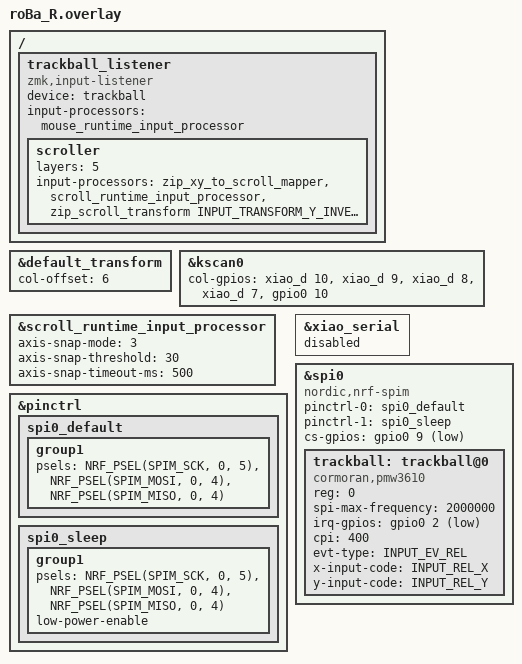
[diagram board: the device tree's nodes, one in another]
#include "roBa.dtsi"
#include <input/processors.dtsi>
#include <input/processors/runtime-input-processor.dtsi>
#include <behaviors/battery_history_request.dtsi>
#include <dt-bindings/zmk/input_transform.h>

&default_transform {
    col-offset = <6>;
};

&kscan0 {
        col-gpios
            = <&xiao_d 10 GPIO_ACTIVE_HIGH>
            , <&xiao_d 9 GPIO_ACTIVE_HIGH>
            , <&xiao_d 8 GPIO_ACTIVE_HIGH>
            , <&xiao_d 7 GPIO_ACTIVE_HIGH>
            , <&gpio0 10 GPIO_ACTIVE_HIGH>
            ;
};

/ {
    trackball_listener {
        status = "okay";
        compatible = "zmk,input-listener";
        device = <&trackball>;
        input-processors = <&mouse_runtime_input_processor>;

        scroller {
            layers = <5>;
            input-processors =
                <&zip_xy_to_scroll_mapper &scroll_runtime_input_processor>,
                <&zip_scroll_transform INPUT_TRANSFORM_Y_INVERT>;
        };
    };
};

/* スクロール軸ロック（斜めスクロール抑制 / 真縦・真横のみ）
 * mode=3 = DOMINANT: 先に動いた軸へ動的にロックし、クロス軸成分を 0 に抑制する。
 *   閾値を超える強いクロス軸入力があるとロックが相手軸へ切り替わる（縦横対称）。
 *   timeout-ms のアイドルでロック解除し、次の動作で軸を選び直す。
 * ※ mode=3 は shkentee fork (feature/dominant-axis-snap-v4) でのみ有効。
 */
&scroll_runtime_input_processor {
    axis-snap-mode = <3>;         /* 3 = DOMINANT（動的・対称の軸ロック） */
    axis-snap-threshold = <30>;   /* ロック確定/切替に必要なクロス軸積算量 */
    axis-snap-timeout-ms = <500>; /* アイドルでロック解除するまでの時間(ms) */
};

&pinctrl {
    spi0_default: spi0_default {
        group1 {
            psels = <NRF_PSEL(SPIM_SCK, 0, 5)>,
                <NRF_PSEL(SPIM_MOSI, 0, 4)>,
                <NRF_PSEL(SPIM_MISO, 0, 4)>;
        };
    };

    spi0_sleep: spi0_sleep {
        group1 {
            psels = <NRF_PSEL(SPIM_SCK, 0, 5)>,
                <NRF_PSEL(SPIM_MOSI, 0, 4)>,
                <NRF_PSEL(SPIM_MISO, 0, 4)>;
            low-power-enable;
        };
    };
};

&xiao_serial { status = "disabled"; };

&spi0 {
    status = "okay";
    compatible = "nordic,nrf-spim";
    pinctrl-0 = <&spi0_default>;
    pinctrl-1 = <&spi0_sleep>;
    pinctrl-names = "default", "sleep";
    cs-gpios = <&gpio0 9 GPIO_ACTIVE_LOW>;

    trackball: trackball@0 {
        status = "okay";
        compatible = "cormoran,pmw3610";
        reg = <0>;
        spi-max-frequency = <2000000>;
        irq-gpios = <&gpio0 2 (GPIO_ACTIVE_LOW | GPIO_PULL_UP)>;
        cpi = <400>;
        evt-type = <INPUT_EV_REL>;
        x-input-code = <INPUT_REL_X>;
        y-input-code = <INPUT_REL_Y>;
    };
};
